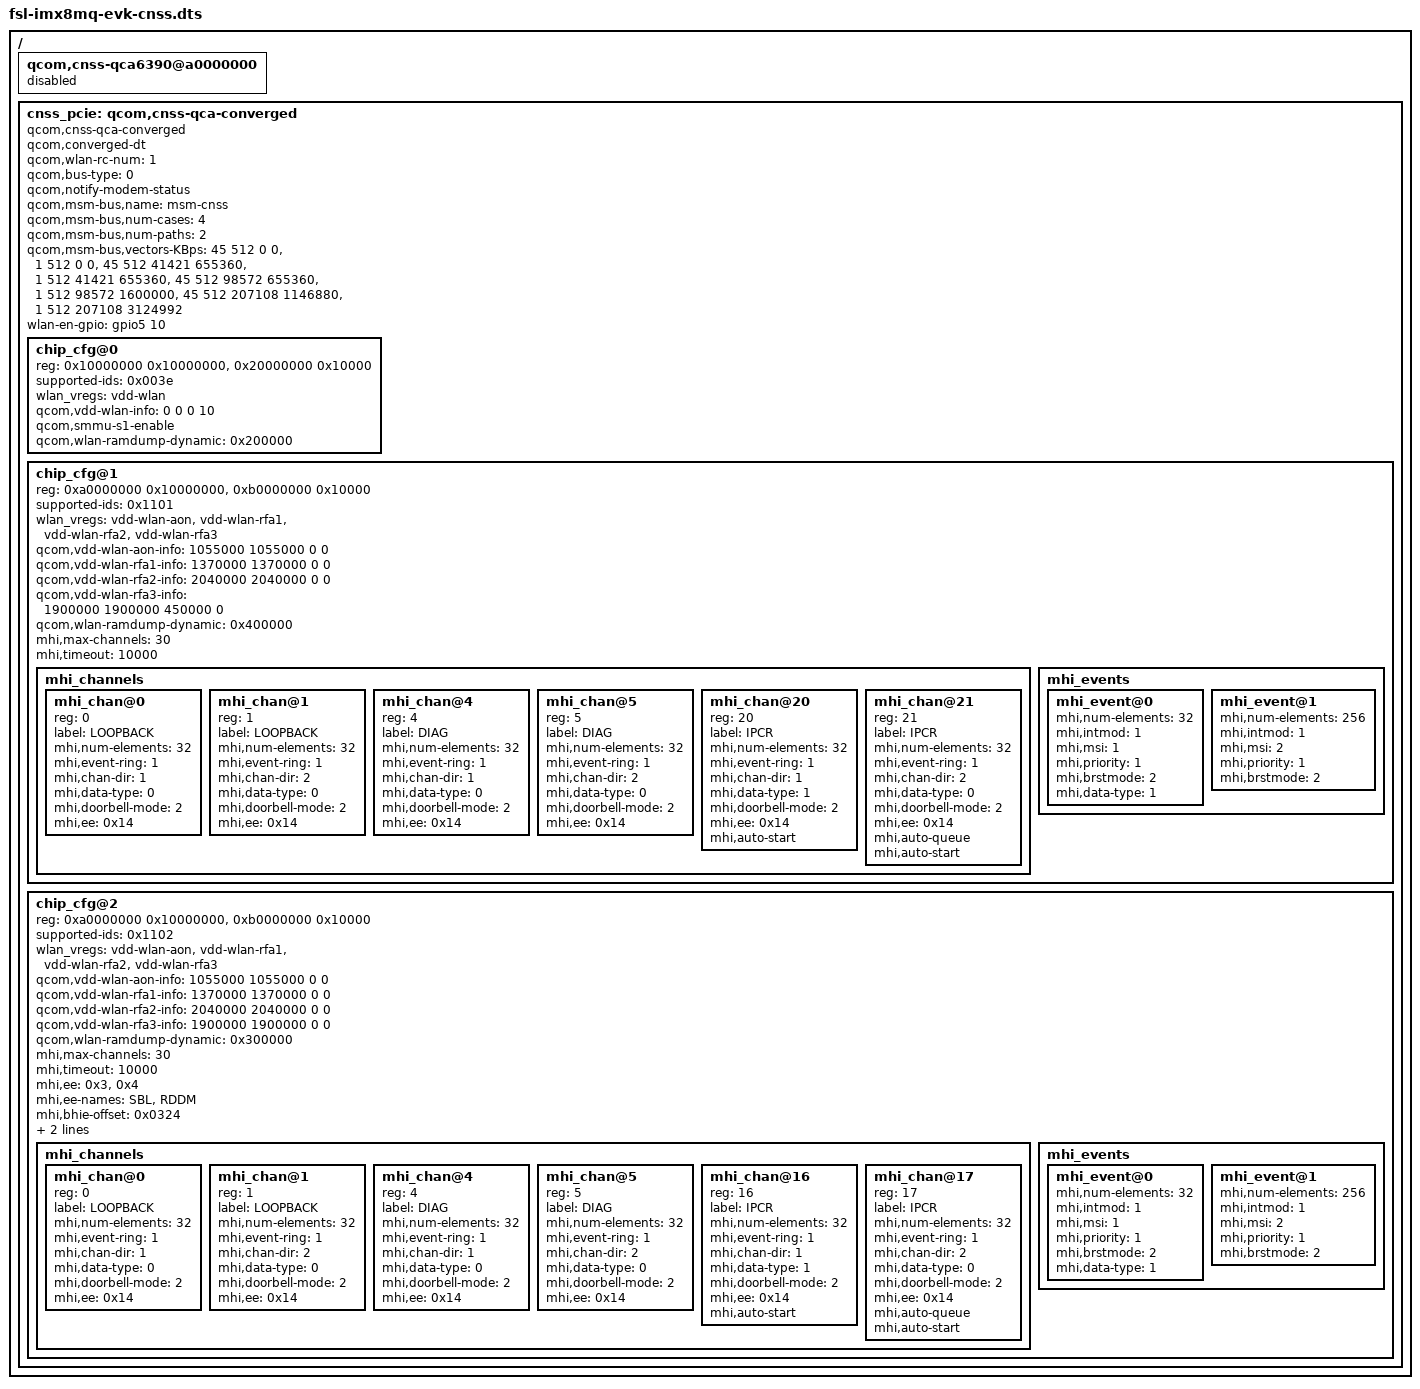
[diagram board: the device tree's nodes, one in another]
/* Copyright (c) 2018-2019, The Linux Foundation. All rights reserved.
 *
 * This program is free software; you can redistribute it and/or modify
 * it under the terms of the GNU General Public License version 2 and
 * only version 2 as published by the Free Software Foundation.
 *
 * This program is distributed in the hope that it will be useful,
 * but WITHOUT ANY WARRANTY; without even the implied warranty of
 * MERCHANTABILITY or FITNESS FOR A PARTICULAR PURPOSE.  See the
 * GNU General Public License for more details.
 */
 / {

	qcom,cnss-qca6390@a0000000 {
		status = "disabled";
	};

	cnss_pcie: qcom,cnss-qca-converged {
		compatible = "qcom,cnss-qca-converged";

		qcom,converged-dt;
		qcom,wlan-rc-num = <1>;
		qcom,bus-type=<0>;
		qcom,notify-modem-status;
		qcom,msm-bus,name = "msm-cnss";
		qcom,msm-bus,num-cases = <4>;
		qcom,msm-bus,num-paths = <2>;
		qcom,msm-bus,vectors-KBps =
			<45 512 0 0>, <1 512 0 0>,
			/* Upto 200 Mbps */
			<45 512 41421 655360>, <1 512 41421 655360>,
			/* Upto 400 Mbps */
			<45 512 98572 655360>, <1 512 98572 1600000>,
			/* Upto 800 Mbps */
			<45 512 207108 1146880>, <1 512 207108 3124992>;

		#address-cells=<1>;
		#size-cells=<1>;
		ranges = <0x10000000 0x10000000 0x10000000>,
		      <0x20000000 0x20000000 0x10000>,
		      <0xa0000000 0xa0000000 0x10000000>,
		      <0xb0000000 0xb0000000 0x10000>;
		      
		wlan-en-gpio = <&gpio5 10 GPIO_ACTIVE_HIGH>;
		
		chip_cfg@0 {
			reg = <0x10000000 0x10000000>,
			    <0x20000000 0x10000>;
			reg-names = "smmu_iova_base", "smmu_iova_ipa";

			supported-ids = <0x003e>;
			wlan_vregs = "vdd-wlan";
			qcom,vdd-wlan-info = <0 0 0 10>;

			qcom,smmu-s1-enable;
			qcom,wlan-ramdump-dynamic = <0x200000>;
		};

		chip_cfg@1 {
			reg = <0xa0000000 0x10000000>,
			    <0xb0000000 0x10000>;
			reg-names = "smmu_iova_base", "smmu_iova_ipa";

			supported-ids = <0x1101>;
			wlan_vregs = "vdd-wlan-aon", "vdd-wlan-rfa1",
				   "vdd-wlan-rfa2", "vdd-wlan-rfa3";
			qcom,vdd-wlan-aon-info = <1055000 1055000 0 0>;
			qcom,vdd-wlan-rfa1-info = <1370000 1370000 0 0>;
			qcom,vdd-wlan-rfa2-info = <2040000 2040000 0 0>;
			qcom,vdd-wlan-rfa3-info = <1900000 1900000 450000 0>;

			qcom,wlan-ramdump-dynamic = <0x400000>;
			mhi,max-channels = <30>;
			mhi,timeout = <10000>;

			mhi_channels {
				#address-cells = <1>;
				#size-cells = <0>;
				mhi_chan@0 {
					reg = <0>;
					label = "LOOPBACK";
					mhi,num-elements = <32>;
					mhi,event-ring = <1>;
					mhi,chan-dir = <1>;
					mhi,data-type = <0>;
					mhi,doorbell-mode = <2>;
					mhi,ee = <0x14>;
				};

				mhi_chan@1 {
					reg = <1>;
					label = "LOOPBACK";
					mhi,num-elements = <32>;
					mhi,event-ring = <1>;
					mhi,chan-dir = <2>;
					mhi,data-type = <0>;
					mhi,doorbell-mode = <2>;
					mhi,ee = <0x14>;
				};

				mhi_chan@4 {
					reg = <4>;
					label = "DIAG";
					mhi,num-elements = <32>;
					mhi,event-ring = <1>;
					mhi,chan-dir = <1>;
					mhi,data-type = <0>;
					mhi,doorbell-mode = <2>;
					mhi,ee = <0x14>;
				};

				mhi_chan@5 {
					reg = <5>;
					label = "DIAG";
					mhi,num-elements = <32>;
					mhi,event-ring = <1>;
					mhi,chan-dir = <2>;
					mhi,data-type = <0>;
					mhi,doorbell-mode = <2>;
					mhi,ee = <0x14>;
				};

				mhi_chan@20 {
					reg = <20>;
					label = "IPCR";
					mhi,num-elements = <32>;
					mhi,event-ring = <1>;
					mhi,chan-dir = <1>;
					mhi,data-type = <1>;
					mhi,doorbell-mode = <2>;
					mhi,ee = <0x14>;
					mhi,auto-start;
				};

				mhi_chan@21 {
					reg = <21>;
					label = "IPCR";
					mhi,num-elements = <32>;
					mhi,event-ring = <1>;
					mhi,chan-dir = <2>;
					mhi,data-type = <0>;
					mhi,doorbell-mode = <2>;
					mhi,ee = <0x14>;
					mhi,auto-queue;
					mhi,auto-start;
				};
			};

			mhi_events {
				mhi_event@0 {
					mhi,num-elements = <32>;
					mhi,intmod = <1>;
					mhi,msi = <1>;
					mhi,priority = <1>;
					mhi,brstmode = <2>;
					mhi,data-type = <1>;
				};

				mhi_event@1 {
					mhi,num-elements = <256>;
					mhi,intmod = <1>;
					mhi,msi = <2>;
					mhi,priority = <1>;
					mhi,brstmode = <2>;
				};
			};
		};

		chip_cfg@2 {
			reg = <0xa0000000 0x10000000>,
			    <0xb0000000 0x10000>;
			reg-names = "smmu_iova_base", "smmu_iova_ipa";

			supported-ids = <0x1102>;
			wlan_vregs = "vdd-wlan-aon", "vdd-wlan-rfa1",
				   "vdd-wlan-rfa2", "vdd-wlan-rfa3";
			qcom,vdd-wlan-aon-info = <1055000 1055000 0 0>;
			qcom,vdd-wlan-rfa1-info = <1370000 1370000 0 0>;
			qcom,vdd-wlan-rfa2-info = <2040000 2040000 0 0>;
			qcom,vdd-wlan-rfa3-info = <1900000 1900000 0 0>;

			qcom,wlan-ramdump-dynamic = <0x300000>;
			mhi,max-channels = <30>;
			mhi,timeout = <10000>;
			mhi,ee = <0x3>, <0x4>;
			mhi,ee-names = "SBL", "RDDM";
			mhi,bhie-offset = <0x0324>;

			pcie-disable-l1;
			pcie-disable-l1ss;

			mhi_channels {
				#address-cells = <1>;
				#size-cells = <0>;
				mhi_chan@0 {
					reg = <0>;
					label = "LOOPBACK";
					mhi,num-elements = <32>;
					mhi,event-ring = <1>;
					mhi,chan-dir = <1>;
					mhi,data-type = <0>;
					mhi,doorbell-mode = <2>;
					mhi,ee = <0x14>;
				};

				mhi_chan@1 {
					reg = <1>;
					label = "LOOPBACK";
					mhi,num-elements = <32>;
					mhi,event-ring = <1>;
					mhi,chan-dir = <2>;
					mhi,data-type = <0>;
					mhi,doorbell-mode = <2>;
					mhi,ee = <0x14>;
				};

				mhi_chan@4 {
					reg = <4>;
					label = "DIAG";
					mhi,num-elements = <32>;
					mhi,event-ring = <1>;
					mhi,chan-dir = <1>;
					mhi,data-type = <0>;
					mhi,doorbell-mode = <2>;
					mhi,ee = <0x14>;
				};

				mhi_chan@5 {
					reg = <5>;
					label = "DIAG";
					mhi,num-elements = <32>;
					mhi,event-ring = <1>;
					mhi,chan-dir = <2>;
					mhi,data-type = <0>;
					mhi,doorbell-mode = <2>;
					mhi,ee = <0x14>;
				};

				mhi_chan@16 {
					reg = <16>;
					label = "IPCR";
					mhi,num-elements = <32>;
					mhi,event-ring = <1>;
					mhi,chan-dir = <1>;
					mhi,data-type = <1>;
					mhi,doorbell-mode = <2>;
					mhi,ee = <0x14>;
					mhi,auto-start;
				};

				mhi_chan@17 {
					reg = <17>;
					label = "IPCR";
					mhi,num-elements = <32>;
					mhi,event-ring = <1>;
					mhi,chan-dir = <2>;
					mhi,data-type = <0>;
					mhi,doorbell-mode = <2>;
					mhi,ee = <0x14>;
					mhi,auto-queue;
					mhi,auto-start;
				};
			};

			mhi_events {
				mhi_event@0 {
					mhi,num-elements = <32>;
					mhi,intmod = <1>;
					mhi,msi = <1>;
					mhi,priority = <1>;
					mhi,brstmode = <2>;
					mhi,data-type = <1>;
				};

				mhi_event@1 {
					mhi,num-elements = <256>;
					mhi,intmod = <1>;
					mhi,msi = <2>;
					mhi,priority = <1>;
					mhi,brstmode = <2>;
				};
			};
		};
	};
};
